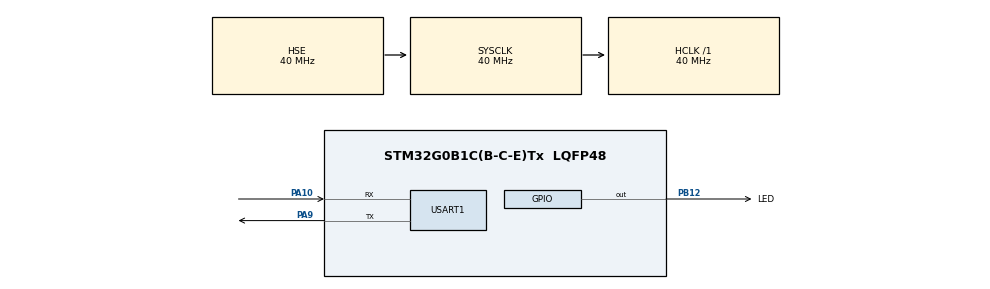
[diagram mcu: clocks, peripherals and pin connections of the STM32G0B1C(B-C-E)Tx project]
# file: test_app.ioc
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Mcu.Family=STM32G0
Mcu.Name=STM32G0B1C(B-C-E)Tx
Mcu.Package=LQFP48
NVIC.TIM3_TIM4_IRQn=true\:0\:0\:false\:false\:true\:true\:true\:true
PA10.Mode=Asynchronous
PA10.Signal=USART1_RX
PA13.Mode=Serial_Wire
PA13.Signal=SYS_SWDIO
PA14-BOOT0.Mode=Serial_Wire
PA14-BOOT0.Signal=SYS_SWCLK
PA9.Mode=Asynchronous
PA9.Signal=USART1_TX
PB12.GPIO_Label=LED
PB12.Signal=GPIO_Output
PF0-OSC_IN\ (PF0).Mode=HSE-External-Oscillator
PF0-OSC_IN\ (PF0).Signal=RCC_OSC_IN
PF1-OSC_OUT\ (PF1).Mode=HSE-External-Oscillator
PF1-OSC_OUT\ (PF1).Signal=RCC_OSC_OUT
ProjectManager.HeapSize=0x200
ProjectManager.StackSize=0x400
ProjectManager.TargetToolchain=STM32CubeIDE
RCC.ADCFreq_Value=40000000
RCC.AHBFreq_Value=40000000
RCC.CortexFreq_Value=40000000
RCC.EXTERNAL_CLOCK_VALUE=48000
RCC.FDCANCLockSelection=RCC_FDCANCLKSOURCE_HSE
RCC.HCLKFreq_Value=40000000
RCC.HSE_VALUE=40000000
RCC.HSI48_VALUE=48000000
RCC.HSI_VALUE=16000000
RCC.LSE_VALUE=32768
RCC.PLLSourceVirtual=RCC_PLLSOURCE_HSE
RCC.SYSCLKFreq_VALUE=40000000
RCC.SYSCLKSource=RCC_SYSCLKSOURCE_HSE
RCC.USBFreq_Value=48000000
RCC.VCOOutputFreq_Value=320000000
TIM3.Period=999
TIM3.Prescaler=39999
USART1.VirtualMode-Asynchronous=VM_ASYNC
VP_TIM3_VS_ClockSourceINT.Mode=Internal
board=custom

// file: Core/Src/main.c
/* USER CODE BEGIN Header */
/**
 ******************************************************************************
 * @file           : main.c
 * @brief          : Main program body
 ******************************************************************************
 * @attention
 *
 * Copyright (c) 2023 STMicroelectronics.
 * All rights reserved.
 *
 * This software is licensed under terms that can be found in the LICENSE file
 * in the root directory of this software component.
 * If no LICENSE file comes with this software, it is provided AS-IS.
 *
 ******************************************************************************
 */
/* USER CODE END Header */
#include "main.h"

/* USER CODE BEGIN PD */

#define FLAGS_ADDRESS (FLASH_BASE + (30 * 0x400))

/* USER CODE END PD */

TIM_HandleTypeDef htim3;

UART_HandleTypeDef huart1;

void SystemClock_Config(void);
static void MX_GPIO_Init(void);
static void MX_TIM3_Init(void);
static void MX_USART1_UART_Init(void);

/* USER CODE BEGIN 0 */

uint8_t tenths_of_seconds = 0;

void HAL_TIM_PeriodElapsedCallback(TIM_HandleTypeDef *htim)
{
	if (htim->Instance == TIM3)
		HAL_GPIO_TogglePin(LED_GPIO_Port, LED_Pin);
	else
		HAL_GPIO_TogglePin(LED_GPIO_Port, LED_Pin);
}

HAL_StatusTypeDef flag_bootloader()
{
	HAL_FLASH_Unlock();
	FLASH_EraseInitTypeDef EraseInitStruct;
	EraseInitStruct.TypeErase = FLASH_TYPEERASE_PAGES;
	EraseInitStruct.Banks = FLASH_BANK_1;

	uint32_t page = (FLAGS_ADDRESS - FLASH_BASE) / (2 * 0x400);

	EraseInitStruct.Page = page;
	EraseInitStruct.NbPages = 1;

	uint32_t PageError;
	if (HAL_FLASHEx_Erase(&EraseInitStruct, &PageError) != HAL_OK) //Erase the Page Before a Write Operation
		return HAL_ERROR;

	HAL_Delay(50);
	HAL_FLASH_Program(FLASH_TYPEPROGRAM_DOUBLEWORD, FLAGS_ADDRESS, 1);
	HAL_Delay(50);
	HAL_FLASH_Lock();

	return HAL_OK;
}

/* USER CODE END 0 */

int main(void)
{

  /* MCU Configuration--------------------------------------------------------*/

  /* Reset of all peripherals, Initializes the Flash interface and the Systick. */
  HAL_Init();

  /* Configure the system clock */
  SystemClock_Config();

  /* Initialize all configured peripherals */
  MX_GPIO_Init();
  MX_TIM3_Init();
  MX_USART1_UART_Init();
  /* USER CODE BEGIN 2 */

  HAL_TIM_Base_Start_IT(&htim3);

  /* USER CODE END 2 */

  /* Infinite loop */
  /* USER CODE BEGIN WHILE */
	while (1)
	{
		uint8_t data;
		HAL_UART_Receive(&huart1, &data, 1, 1000);
		HAL_UART_Transmit(&huart1, &data, 1, 1000);
		if (data == 'r')
		{
			flag_bootloader();
			NVIC_SystemReset();
		}

    /* USER CODE END WHILE */

	}
}

void SystemClock_Config(void)
{
  RCC_OscInitTypeDef RCC_OscInitStruct = {0};
  RCC_ClkInitTypeDef RCC_ClkInitStruct = {0};

  /** Configure the main internal regulator output voltage
  */
  HAL_PWREx_ControlVoltageScaling(PWR_REGULATOR_VOLTAGE_SCALE1);

  /** Initializes the RCC Oscillators according to the specified parameters
  * in the RCC_OscInitTypeDef structure.
  */
  RCC_OscInitStruct.OscillatorType = RCC_OSCILLATORTYPE_HSE;
  RCC_OscInitStruct.HSEState = RCC_HSE_ON;
  RCC_OscInitStruct.PLL.PLLState = RCC_PLL_NONE;
  if (HAL_RCC_OscConfig(&RCC_OscInitStruct) != HAL_OK)
  {
    Error_Handler();
  }

  /** Initializes the CPU, AHB and APB buses clocks
  */
  RCC_ClkInitStruct.ClockType = RCC_CLOCKTYPE_HCLK|RCC_CLOCKTYPE_SYSCLK
                              |RCC_CLOCKTYPE_PCLK1;
  RCC_ClkInitStruct.SYSCLKSource = RCC_SYSCLKSOURCE_HSE;
  RCC_ClkInitStruct.AHBCLKDivider = RCC_SYSCLK_DIV1;
  RCC_ClkInitStruct.APB1CLKDivider = RCC_HCLK_DIV1;

  if (HAL_RCC_ClockConfig(&RCC_ClkInitStruct, FLASH_LATENCY_1) != HAL_OK)
  {
    Error_Handler();
  }
}

static void MX_TIM3_Init(void)
{

  TIM_ClockConfigTypeDef sClockSourceConfig = {0};
  TIM_MasterConfigTypeDef sMasterConfig = {0};

  htim3.Instance = TIM3;
  htim3.Init.Prescaler = 39999;
  htim3.Init.CounterMode = TIM_COUNTERMODE_UP;
  htim3.Init.Period = 999;
  htim3.Init.ClockDivision = TIM_CLOCKDIVISION_DIV1;
  htim3.Init.AutoReloadPreload = TIM_AUTORELOAD_PRELOAD_DISABLE;
  if (HAL_TIM_Base_Init(&htim3) != HAL_OK)
  {
    Error_Handler();
  }
  sClockSourceConfig.ClockSource = TIM_CLOCKSOURCE_INTERNAL;
  if (HAL_TIM_ConfigClockSource(&htim3, &sClockSourceConfig) != HAL_OK)
  {
    Error_Handler();
  }
  sMasterConfig.MasterOutputTrigger = TIM_TRGO_RESET;
  sMasterConfig.MasterSlaveMode = TIM_MASTERSLAVEMODE_DISABLE;
  if (HAL_TIMEx_MasterConfigSynchronization(&htim3, &sMasterConfig) != HAL_OK)
  {
    Error_Handler();
  }

}

static void MX_USART1_UART_Init(void)
{

  huart1.Instance = USART1;
  huart1.Init.BaudRate = 115200;
  huart1.Init.WordLength = UART_WORDLENGTH_8B;
  huart1.Init.StopBits = UART_STOPBITS_1;
  huart1.Init.Parity = UART_PARITY_NONE;
  huart1.Init.Mode = UART_MODE_TX_RX;
  huart1.Init.HwFlowCtl = UART_HWCONTROL_NONE;
  huart1.Init.OverSampling = UART_OVERSAMPLING_16;
  huart1.Init.OneBitSampling = UART_ONE_BIT_SAMPLE_DISABLE;
  huart1.Init.ClockPrescaler = UART_PRESCALER_DIV1;
  huart1.AdvancedInit.AdvFeatureInit = UART_ADVFEATURE_NO_INIT;
  if (HAL_UART_Init(&huart1) != HAL_OK)
  {
    Error_Handler();
  }
  if (HAL_UARTEx_SetTxFifoThreshold(&huart1, UART_TXFIFO_THRESHOLD_1_8) != HAL_OK)
  {
    Error_Handler();
  }
  if (HAL_UARTEx_SetRxFifoThreshold(&huart1, UART_RXFIFO_THRESHOLD_1_8) != HAL_OK)
  {
    Error_Handler();
  }
  if (HAL_UARTEx_DisableFifoMode(&huart1) != HAL_OK)
  {
    Error_Handler();
  }

}

static void MX_GPIO_Init(void)
{
  GPIO_InitTypeDef GPIO_InitStruct = {0};

  /* GPIO Ports Clock Enable */
  __HAL_RCC_GPIOF_CLK_ENABLE();
  __HAL_RCC_GPIOB_CLK_ENABLE();
  __HAL_RCC_GPIOA_CLK_ENABLE();

  /*Configure GPIO pin Output Level */
  HAL_GPIO_WritePin(LED_GPIO_Port, LED_Pin, GPIO_PIN_RESET);

  /*Configure GPIO pin : LED_Pin */
  GPIO_InitStruct.Pin = LED_Pin;
  GPIO_InitStruct.Mode = GPIO_MODE_OUTPUT_PP;
  GPIO_InitStruct.Pull = GPIO_NOPULL;
  GPIO_InitStruct.Speed = GPIO_SPEED_FREQ_LOW;
  HAL_GPIO_Init(LED_GPIO_Port, &GPIO_InitStruct);

}

void Error_Handler(void)
{
	__disable_irq();
	while (1)
	{
	}
}
